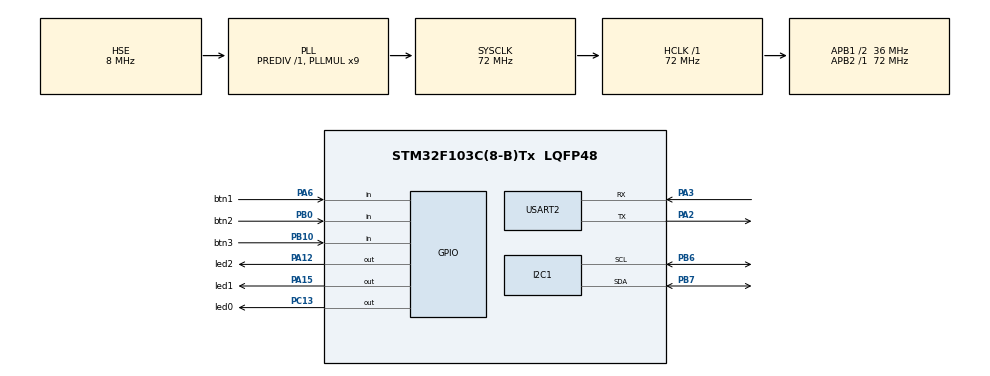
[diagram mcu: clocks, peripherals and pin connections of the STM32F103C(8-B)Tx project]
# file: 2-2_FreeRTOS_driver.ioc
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FREERTOS.BinarySemaphores01=myBinarySem01,Dynamic,NULL,Available
FREERTOS.CountingSemaphores01=myCountingSem01,3,Dynamic,NULL,0
FREERTOS.Queues01=ButtonQueue,1,uint8_t,0,Dynamic,NULL,NULL;TimeQueue,1,uint16_t,0,Dynamic,NULL,NULL;printQueue,1,uint8_t *,0,Dynamic,NULL,NULL
FREERTOS.Tasks01=defaultTask,24,128,StartDefaultTask,Default,NULL,Dynamic,NULL,NULL;myTask02,8,128,StartTask02,Default,1,Dynamic,NULL,NULL;myTask03,8,128,StartTask03,Default,NULL,Dynamic,NULL,NULL;LEDTask,8,128,LEDTaskFunc,Default,NULL,Dynamic,NULL,NULL;ButtonTask,8,128,ButtonTaskFunc,Default,NULL,Dynamic,NULL,NULL
FREERTOS.configTOTAL_HEAP_SIZE=4800
Mcu.Family=STM32F1
Mcu.Name=STM32F103C(8-B)Tx
Mcu.Package=LQFP48
NVIC.PriorityGroup=NVIC_PRIORITYGROUP_4
NVIC.TIM1_BRK_IRQn=true\:5\:0\:false\:false\:true\:true\:true\:true\:true
NVIC.TIM1_CC_IRQn=true\:5\:0\:false\:false\:true\:true\:true\:true\:true
NVIC.TIM1_TRG_COM_IRQn=true\:5\:0\:false\:false\:true\:true\:true\:true\:true
NVIC.TIM1_UP_IRQn=true\:5\:0\:false\:false\:true\:true\:true\:true\:true
NVIC.TIM4_IRQn=true\:15\:0\:false\:false\:true\:false\:false\:true\:true
NVIC.TimeBase=TIM4_IRQn
NVIC.TimeBaseIP=TIM4
NVIC.USART2_IRQn=true\:5\:0\:false\:false\:true\:true\:true\:true\:true
PA12.GPIO_Label=led2
PA12.Signal=GPIO_Output
PA13.Mode=Serial_Wire
PA13.Signal=SYS_JTMS-SWDIO
PA14.Mode=Serial_Wire
PA14.Signal=SYS_JTCK-SWCLK
PA15.GPIO_Label=led1
PA15.Signal=GPIO_Output
PA2.Mode=Asynchronous
PA2.Signal=USART2_TX
PA3.Mode=Asynchronous
PA3.Signal=USART2_RX
PA6.GPIO_Label=btn1
PA6.GPIO_PuPd=GPIO_PULLUP
PA6.Signal=GPIO_Input
PB0.GPIO_Label=btn2
PB0.GPIO_PuPd=GPIO_PULLUP
PB0.Signal=GPIO_Input
PB10.GPIO_Label=btn3
PB10.GPIO_PuPd=GPIO_PULLUP
PB10.Signal=GPIO_Input
PB6.Mode=I2C
PB6.Signal=I2C1_SCL
PB7.Mode=I2C
PB7.Signal=I2C1_SDA
PC13-TAMPER-RTC.GPIO_Label=led0
PC13-TAMPER-RTC.Signal=GPIO_Output
PC14-OSC32_IN.Mode=LSE-External-Oscillator
PC14-OSC32_IN.Signal=RCC_OSC32_IN
PC15-OSC32_OUT.Mode=LSE-External-Oscillator
PC15-OSC32_OUT.Signal=RCC_OSC32_OUT
PD0-OSC_IN.Mode=HSE-External-Oscillator
PD0-OSC_IN.Signal=RCC_OSC_IN
PD1-OSC_OUT.Mode=HSE-External-Oscillator
PD1-OSC_OUT.Signal=RCC_OSC_OUT
ProjectManager.HeapSize=0x200
ProjectManager.StackSize=0x400
ProjectManager.TargetToolchain=MDK-ARM V5.32
RCC.AHBFreq_Value=72000000
RCC.APB1CLKDivider=RCC_HCLK_DIV2
RCC.APB1Freq_Value=36000000
RCC.APB1TimFreq_Value=72000000
RCC.APB2Freq_Value=72000000
RCC.APB2TimFreq_Value=72000000
RCC.HCLKFreq_Value=72000000
RCC.PLLMUL=RCC_PLL_MUL9
RCC.PLLSourceVirtual=RCC_PLLSOURCE_HSE
RCC.SYSCLKFreq_VALUE=72000000
RCC.SYSCLKSource=RCC_SYSCLKSOURCE_PLLCLK
RCC.USBFreq_Value=72000000
TIM1.AutoReloadPreload=TIM_AUTORELOAD_PRELOAD_ENABLE
TIM1.Period=1000 -1
TIM1.Prescaler=72 - 1
USART2.VirtualMode=VM_ASYNC
VP_FREERTOS_VS_CMSIS_V2.Mode=CMSIS_V2
VP_SYS_VS_tim4.Mode=TIM4
VP_TIM1_VS_ClockSourceINT.Mode=Internal
board=custom

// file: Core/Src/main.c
/* USER CODE BEGIN Header */
/**
 ******************************************************************************
 * @file           : main.c
 * @brief          : Main program body
 ******************************************************************************
 * @attention
 *
 * Copyright (c) 2026 STMicroelectronics.
 * All rights reserved.
 *
 * This software is licensed under terms that can be found in the LICENSE file
 * in the root directory of this software component.
 * If no LICENSE file comes with this software, it is provided AS-IS.
 *
 ******************************************************************************
 */
/* USER CODE END Header */
#include "main.h"
#include "cmsis_os.h"
#include "i2c.h"
#include "tim.h"
#include "usart.h"
#include "gpio.h"

/* USER CODE BEGIN Includes */
#include "User_task.h"

/* USER CODE END Includes */

void SystemClock_Config(void);
void MX_FREERTOS_Init(void);

int main(void)
{

  /* MCU Configuration--------------------------------------------------------*/

  /* Reset of all peripherals, Initializes the Flash interface and the Systick. */
  HAL_Init();

  /* Configure the system clock */
  SystemClock_Config();

  /* Initialize all configured peripherals */
  MX_GPIO_Init();
  MX_USART2_UART_Init();
  MX_TIM1_Init();
  MX_I2C1_Init();
  /* USER CODE BEGIN 2 */
  HAL_GPIO_WritePin(GPIOC, GPIO_PIN_13, GPIO_PIN_SET);
  HAL_TIM_Base_Start_IT(&htim1);

  /* USER CODE END 2 */

  /* Init scheduler */
  osKernelInitialize();  /* Call init function for freertos objects (in cmsis_os2.c) */
  MX_FREERTOS_Init();

  /* Start scheduler */
  osKernelStart();

  /* We should never get here as control is now taken by the scheduler */

  /* Infinite loop */
  /* USER CODE BEGIN WHILE */
  while (1)
  {
    //    HAL_GPIO_TogglePin(GPIOC, GPIO_PIN_13);
    //    printf("Hello World\r\n");
    //    HAL_Delay(500);
    /* USER CODE END WHILE */

  }
}

void SystemClock_Config(void)
{
  RCC_OscInitTypeDef RCC_OscInitStruct = {0};
  RCC_ClkInitTypeDef RCC_ClkInitStruct = {0};

  /** Initializes the RCC Oscillators according to the specified parameters
  * in the RCC_OscInitTypeDef structure.
  */
  RCC_OscInitStruct.OscillatorType = RCC_OSCILLATORTYPE_HSE;
  RCC_OscInitStruct.HSEState = RCC_HSE_ON;
  RCC_OscInitStruct.HSEPredivValue = RCC_HSE_PREDIV_DIV1;
  RCC_OscInitStruct.HSIState = RCC_HSI_ON;
  RCC_OscInitStruct.PLL.PLLState = RCC_PLL_ON;
  RCC_OscInitStruct.PLL.PLLSource = RCC_PLLSOURCE_HSE;
  RCC_OscInitStruct.PLL.PLLMUL = RCC_PLL_MUL9;
  if (HAL_RCC_OscConfig(&RCC_OscInitStruct) != HAL_OK)
  {
    Error_Handler();
  }

  /** Initializes the CPU, AHB and APB buses clocks
  */
  RCC_ClkInitStruct.ClockType = RCC_CLOCKTYPE_HCLK|RCC_CLOCKTYPE_SYSCLK
                              |RCC_CLOCKTYPE_PCLK1|RCC_CLOCKTYPE_PCLK2;
  RCC_ClkInitStruct.SYSCLKSource = RCC_SYSCLKSOURCE_PLLCLK;
  RCC_ClkInitStruct.AHBCLKDivider = RCC_SYSCLK_DIV1;
  RCC_ClkInitStruct.APB1CLKDivider = RCC_HCLK_DIV2;
  RCC_ClkInitStruct.APB2CLKDivider = RCC_HCLK_DIV1;

  if (HAL_RCC_ClockConfig(&RCC_ClkInitStruct, FLASH_LATENCY_2) != HAL_OK)
  {
    Error_Handler();
  }
}

void HAL_TIM_PeriodElapsedCallback(TIM_HandleTypeDef *htim)
{
  if (htim->Instance == TIM4)
  {
    HAL_IncTick();
  }
}

void Error_Handler(void)
{
  __disable_irq();
  while (1)
  {
  }
}

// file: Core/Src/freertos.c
/* USER CODE BEGIN Header */
/**
 ******************************************************************************
 * File Name          : freertos.c
 * Description        : Code for freertos applications
 ******************************************************************************
 * @attention
 *
 * Copyright (c) 2026 STMicroelectronics.
 * All rights reserved.
 *
 * This software is licensed under terms that can be found in the LICENSE file
 * in the root directory of this software component.
 * If no LICENSE file comes with this software, it is provided AS-IS.
 *
 ******************************************************************************
 */
/* USER CODE END Header */

#include "FreeRTOS.h"
#include "task.h"
#include "main.h"
#include "cmsis_os.h"

/* USER CODE BEGIN Includes */
#include "user_task.h"

/* USER CODE END Includes */

/* Definitions for defaultTask */
osThreadId_t defaultTaskHandle;
const osThreadAttr_t defaultTask_attributes = {
  .name = "defaultTask",
  .stack_size = 128 * 4,
  .priority = (osPriority_t) osPriorityNormal,
};
/* Definitions for myTask02 */
osThreadId_t myTask02Handle;
const osThreadAttr_t myTask02_attributes = {
  .name = "myTask02",
  .stack_size = 128 * 4,
  .priority = (osPriority_t) osPriorityLow,
};
/* Definitions for myTask03 */
osThreadId_t myTask03Handle;
const osThreadAttr_t myTask03_attributes = {
  .name = "myTask03",
  .stack_size = 128 * 4,
  .priority = (osPriority_t) osPriorityLow,
};
/* Definitions for LEDTask */
osThreadId_t LEDTaskHandle;
const osThreadAttr_t LEDTask_attributes = {
  .name = "LEDTask",
  .stack_size = 128 * 4,
  .priority = (osPriority_t) osPriorityLow,
};
/* Definitions for ButtonTask */
osThreadId_t ButtonTaskHandle;
const osThreadAttr_t ButtonTask_attributes = {
  .name = "ButtonTask",
  .stack_size = 128 * 4,
  .priority = (osPriority_t) osPriorityLow,
};
/* Definitions for ButtonQueue */
osMessageQueueId_t ButtonQueueHandle;
const osMessageQueueAttr_t ButtonQueue_attributes = {
  .name = "ButtonQueue"
};
/* Definitions for TimeQueue */
osMessageQueueId_t TimeQueueHandle;
const osMessageQueueAttr_t TimeQueue_attributes = {
  .name = "TimeQueue"
};
/* Definitions for printQueue */
osMessageQueueId_t printQueueHandle;
const osMessageQueueAttr_t printQueue_attributes = {
  .name = "printQueue"
};
/* Definitions for myBinarySem01 */
osSemaphoreId_t myBinarySem01Handle;
const osSemaphoreAttr_t myBinarySem01_attributes = {
  .name = "myBinarySem01"
};
/* Definitions for myCountingSem01 */
osSemaphoreId_t myCountingSem01Handle;
const osSemaphoreAttr_t myCountingSem01_attributes = {
  .name = "myCountingSem01"
};

void StartDefaultTask(void *argument);
void StartTask02(void *argument);
void StartTask03(void *argument);
void LEDTaskFunc(void *argument);
void ButtonTaskFunc(void *argument);

void MX_FREERTOS_Init(void); /* (MISRA C 2004 rule 8.1) */

void MX_FREERTOS_Init(void) {

  /* Create the semaphores(s) */
  /* creation of myBinarySem01 */
  myBinarySem01Handle = osSemaphoreNew(1, 1, &myBinarySem01_attributes);

  /* creation of myCountingSem01 */
  myCountingSem01Handle = osSemaphoreNew(3, 0, &myCountingSem01_attributes);

  /* Create the queue(s) */
  /* creation of ButtonQueue */
  ButtonQueueHandle = osMessageQueueNew (1, sizeof(uint8_t), &ButtonQueue_attributes);

  /* creation of TimeQueue */
  TimeQueueHandle = osMessageQueueNew (1, sizeof(uint16_t), &TimeQueue_attributes);

  /* creation of printQueue */
  printQueueHandle = osMessageQueueNew (1, sizeof(uint8_t *), &printQueue_attributes);

  /* Create the thread(s) */
  /* creation of defaultTask */
  defaultTaskHandle = osThreadNew(StartDefaultTask, NULL, &defaultTask_attributes);

  /* creation of myTask02 */
  myTask02Handle = osThreadNew(StartTask02, (void*) 1, &myTask02_attributes);

  /* creation of myTask03 */
  myTask03Handle = osThreadNew(StartTask03, NULL, &myTask03_attributes);

  /* creation of LEDTask */
  LEDTaskHandle = osThreadNew(LEDTaskFunc, NULL, &LEDTask_attributes);

  /* creation of ButtonTask */
  ButtonTaskHandle = osThreadNew(ButtonTaskFunc, NULL, &ButtonTask_attributes);

}

void StartDefaultTask(void *argument)
{
  /* USER CODE BEGIN StartDefaultTask */
  /* Infinite loop */
  for (;;)
  {
    osDelay(10);
  }
  /* USER CODE END StartDefaultTask */
}

void StartTask02(void *argument)
{
  /* USER CODE BEGIN StartTask02 */
  /* Infinite loop */
  for (;;)
  {
    User_Task_1();
    // osDelay(1);
  }
  /* USER CODE END StartTask02 */
}

void StartTask03(void *argument)
{
  /* USER CODE BEGIN StartTask03 */
  /* Infinite loop */
  for (;;)
  {
    User_Task_2();
    // osDelay(1);
  }
  /* USER CODE END StartTask03 */
}

void LEDTaskFunc(void *argument)
{
  /* USER CODE BEGIN LEDTaskFunc */
  /* Infinite loop */
  for (;;)
  {
    vLEDTask();
  }
  /* USER CODE END LEDTaskFunc */
}

void ButtonTaskFunc(void *argument)
{
  /* USER CODE BEGIN ButtonTaskFunc */
  /* Infinite loop */
  for (;;)
  {
    vButtonScan();
  }
  /* USER CODE END ButtonTaskFunc */
}
